# MK20D5 register map
Vendor: Freescale Semiconductor, Inc.; Series: Kinetis_K; File version: 1.6
CPU: CM4 r0p1, little endian, no MPU, no FPU, VTOR, 4 interrupt priority bits
Registers are 32-bit, read-write, reset 0x0 unless marked. A register's access mark holds for its fields unless they carry their own. Offsets are from the block's base; [hi:lo] are bit positions; {n}, {i} and the like mark numbered series; 'fields as' and 'values as' point back to an identical list.

## VREF — Voltage Reference
Base 0x40074000; register names take the prefix VREF_
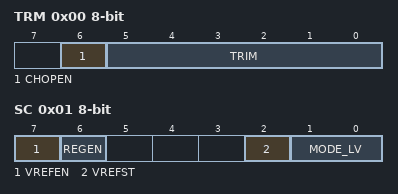
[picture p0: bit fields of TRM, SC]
0x00 TRM 8-bit — VREF Trim Register
  [6] CHOPEN — Chop oscillator enable. When set, internal chopping operation is enabled and the internal analog offset will be minimized.
    0=Chop oscillator is disabled; 1=Chop oscillator is enabled
  [5:0] TRIM — Trim bits
    0=Min; 63=Max
0x01 SC 8-bit — VREF Status and Control Register
  [7] VREFEN — Internal Voltage Reference enable
    0=The module is disabled; 1=The module is enabled
  [6] REGEN — Regulator enable
    0=Internal 1.75 V regulator is disabled; 1=Internal 1.75 V regulator is enabled
  [2] VREFST ro — Internal Voltage Reference stable
    0=The module is disabled or not stable; 1=The module is stable
  [1:0] MODE_LV — Buffer Mode selection
    0=Bandgap on only, for stabilization and startup; 1=Low-power buffer mode enabled; 2=Tight-regulation buffer enabled

## LLWU — Low leakage wakeup unit
Base 0x4007C000; register names take the prefix LLWU_
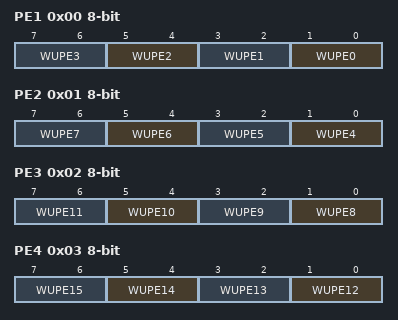
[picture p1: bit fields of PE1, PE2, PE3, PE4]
0x00 PE1 8-bit — LLWU Pin Enable 1 Register
  [all] fields
    0=External input pin disabled as wakeup input; 1=External input pin enabled with rising edge detection; 2=External input pin enabled with falling edge detection; 3=External input pin enabled with any change detection
  [2n+1:2n] WUPE{n} (n=0..3) — Wakeup Pin Enable for LLWU_P{n}
0x01 PE2 8-bit — LLWU Pin Enable 2 Register
  [all] fields
    values as the fields of PE1
  [2n-7:2n-8] WUPE{n} (n=4..7) — Wakeup Pin Enable for LLWU_P{n}
0x02 PE3 8-bit — LLWU Pin Enable 3 Register
  [all] fields
    values as the fields of PE1
  [2n-15:2n-16] WUPE{n} (n=8..11) — Wakeup Pin Enable for LLWU_P{n}
0x03 PE4 8-bit — LLWU Pin Enable 4 Register
  [all] fields
    values as the fields of PE1
  [2n-23:2n-24] WUPE{n} (n=12..15) — Wakeup Pin Enable for LLWU_P{n}
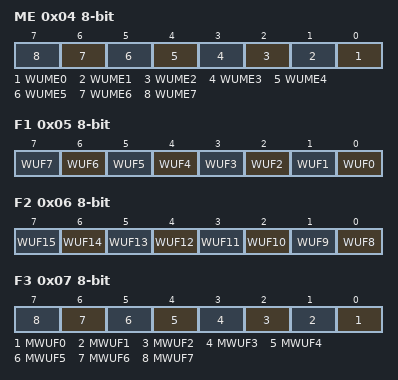
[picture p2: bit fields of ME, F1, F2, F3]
0x04 ME 8-bit — LLWU Module Enable Register
  [all] fields
    0=Internal module flag not used as wakeup source; 1=Internal module flag used as wakeup source
  [n] WUME{n} (n=0..7) — Wakeup Module Enable for Module {n}
0x05 F1 8-bit — LLWU Flag 1 Register
  [n] WUF{n} (n=0..7) — Wakeup Flag for LLWU_P{n}
    0=LLWU_P{n} input was not a wakeup source; 1=LLWU_P{n} input was a wakeup source
0x06 F2 8-bit — LLWU Flag 2 Register
  [n-8] WUF{n} (n=8..15) — Wakeup Flag for LLWU_P{n}
    values as F1.WUF0
0x07 F3 8-bit ro — LLWU Flag 3 Register
  [n] MWUF{n} (n=0..7) — Wakeup flag for module {n}
    0=Module {n} input was not a wakeup source; 1=Module {n} input was a wakeup source
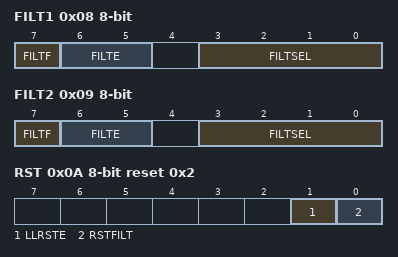
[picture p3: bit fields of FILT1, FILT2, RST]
0x08 FILT1 8-bit — LLWU Pin Filter 1 Register
  [7] FILTF — Filter Detect Flag
    0=Pin Filter 1 was not a wakeup source; 1=Pin Filter 1 was a wakeup source
  [6:5] FILTE — Digital Filter on External Pin
    0=Filter disabled; 1=Filter posedge detect enabled; 2=Filter negedge detect enabled; 3=Filter any edge detect enabled
  [3:0] FILTSEL — Filter pin select
    0=Select LLWU_P0 for filter; 15=Select LLWU_P15 for filter
0x09 FILT2 8-bit — LLWU Pin Filter 2 Register
  [7] FILTF — Filter Detect Flag
    0=Pin Filter 2 was not a wakeup source; 1=Pin Filter 2 was a wakeup source
  [6:5] FILTE — Digital Filter on External Pin
    values as FILT1.FILTE
  [3:0] FILTSEL — Filter pin select
    0=Select LLWU_P0 for filter; 15=Select LLWU_P15 for filter
0x0A RST 8-bit reset 0x2 — LLWU Reset Enable Register
  [1] LLRSTE — Low Leakage mode RESET enable
    0=RESET pin not enabled as a leakage mode exit source; 1=RESET pin enabled as a low leakage mode exit source
  [0] RSTFILT — Digital Filter on RESET Pin
    0=Filter not enabled; 1=Filter enabled

## PMC — Power Management Controller
Base 0x4007D000; register names take the prefix PMC_
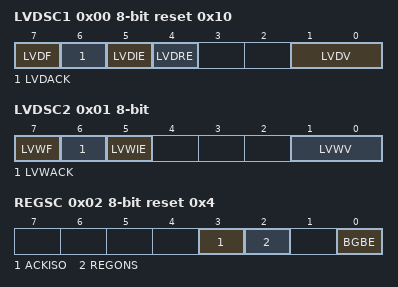
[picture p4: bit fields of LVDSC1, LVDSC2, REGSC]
0x00 LVDSC1 8-bit reset 0x10 — Low Voltage Detect Status and Control 1 Register
  [7] LVDF ro — Low-Voltage Detect Flag
    0=Low-voltage event not detected; 1=Low-voltage event detected
  [6] LVDACK wo — Low-Voltage Detect Acknowledge
  [5] LVDIE — Low-Voltage Detect Interrupt Enable
    0=Hardware interrupt disabled (use polling); 1=Request a hardware interrupt when LVDF = 1
  [4] LVDRE — Low-Voltage Detect Reset Enable
    0=LVDF does not generate hardware resets; 1=Force an MCU reset when LVDF = 1
  [1:0] LVDV — Low-Voltage Detect Voltage Select
    0=Low trip point selected (V LVD = V LVDL ); 1=High trip point selected (V LVD = V LVDH )
0x01 LVDSC2 8-bit — Low Voltage Detect Status and Control 2 Register
  [7] LVWF ro — Low-Voltage Warning Flag
    0=Low-voltage warning event not detected; 1=Low-voltage warning event detected
  [6] LVWACK wo — Low-Voltage Warning Acknowledge
  [5] LVWIE — Low-Voltage Warning Interrupt Enable
    0=Hardware interrupt disabled (use polling); 1=Request a hardware interrupt when LVWF = 1
  [1:0] LVWV — Low-Voltage Warning Voltage Select
    0=Low trip point selected (V LVW = V LVW1 ); 1=Mid 1 trip point selected (V LVW = V LVW2 ); 2=Mid 2 trip point selected (V LVW = V LVW3 ); 3=High trip point selected (V LVW = V LVW4 )
0x02 REGSC 8-bit reset 0x4 — Regulator Status and Control Register
  [3] ACKISO — Acknowledge Isolation
    0=Peripherals and I/O pads are in normal run state; 1=Certain peripherals and I/O pads are in an isolated and latched state
  [2] REGONS ro — Regulator in Run Regulation Status
    0=Regulator is in stop regulation or in transition to/from it; 1=Regulator is in run regulation
  [0] BGBE — Bandgap Buffer Enable
    0=Bandgap buffer not enabled; 1=Bandgap buffer enabled
